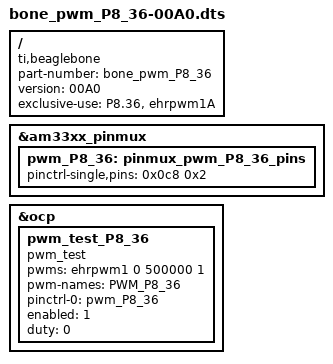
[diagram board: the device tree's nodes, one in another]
/*
 * Copyright (C) 2013 CircuitCo
 * Copyright (C) 2013 Texas Instruments
 *
 * This program is free software; you can redistribute it and/or modify
 * it under the terms of the GNU General Public License version 2 as
 * published by the Free Software Foundation.
 */
/dts-v1/;
/plugin/;

/ {
	compatible = "ti,beaglebone", "ti,beaglebone-black", "ti,beaglebone-green";

	/* identification */
	part-number = "bone_pwm_P8_36";
	version = "00A0";

	/* state the resources this cape uses */
	exclusive-use =
		/* the pin header uses */
		"P8.36",		/* pwm: ehrpwm1A */
		/* the hardware IP uses */
		"ehrpwm1A";

	fragment@0 {
		target = <&am33xx_pinmux>;
		__overlay__ {
			pwm_P8_36: pinmux_pwm_P8_36_pins {
				pinctrl-single,pins = <0x0c8  0x2>; /* P8_36 (ZCZ ball U3) | MODE 2 */
			};
		};
	};

	fragment@1 {
		target = <&ocp>;
		__overlay__ {
			pwm_test_P8_36 {
				compatible	= "pwm_test";
				pwms 		= <&ehrpwm1 0 500000 1>;
				pwm-names 	= "PWM_P8_36";
			    pinctrl-names	= "default";
			    pinctrl-0	= <&pwm_P8_36>;
				enabled		= <1>;
				duty		= <0>;
				status 		= "okay";
			};
		};
	};
};
